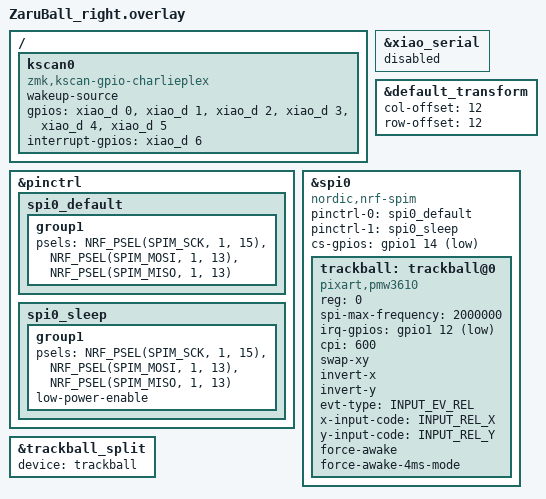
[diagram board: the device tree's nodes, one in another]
#include "ZaruBall.dtsi"
#include <input/processors.dtsi>
#include <dt-bindings/zmk/input_transform.h>

&xiao_serial { status = "disabled"; };

// matrix transformでのピン数オフセット
&default_transform { // Offset of 7 because the left side has 2 columns
    col-offset = <12>;
    row-offset = <12>;
};

/ {
    kscan0: kscan0 {
        compatible = "zmk,kscan-gpio-charlieplex";
        wakeup-source;
        gpios
            = <&xiao_d 0 GPIO_ACTIVE_HIGH>//M1
            , <&xiao_d 1 GPIO_ACTIVE_HIGH>//M2
            , <&xiao_d 2 GPIO_ACTIVE_HIGH>//M3
            , <&xiao_d 3 GPIO_ACTIVE_HIGH>//M4
            , <&xiao_d 4 GPIO_ACTIVE_HIGH>//M5
            , <&xiao_d 5 GPIO_ACTIVE_HIGH>//M6
            ;
        interrupt-gpios = <&xiao_d 6 (GPIO_ACTIVE_HIGH | GPIO_PULL_DOWN)>;//IGPIO
     };
};

&pinctrl {
    spi0_default: spi0_default {
        group1 {
            psels = <NRF_PSEL(SPIM_SCK, 1, 15)>,
                <NRF_PSEL(SPIM_MOSI, 1, 13)>,
                <NRF_PSEL(SPIM_MISO, 1, 13)>;
        };
    };

    spi0_sleep: spi0_sleep {
        group1 {
            psels = <NRF_PSEL(SPIM_SCK, 1, 15)>,
                <NRF_PSEL(SPIM_MOSI, 1, 13)>,
                <NRF_PSEL(SPIM_MISO, 1, 13)>;
            low-power-enable;
        };
    };
};

#include <zephyr/dt-bindings/input/input-event-codes.h>

&spi0 {
    status = "okay";
    compatible = "nordic,nrf-spim";
    pinctrl-0 = <&spi0_default>;
    pinctrl-1 = <&spi0_sleep>;
    pinctrl-names = "default", "sleep";
    cs-gpios = <&gpio1 14 GPIO_ACTIVE_LOW>;

    trackball: trackball@0 {
        status = "okay";
        compatible = "pixart,pmw3610";
        reg = <0>;
        spi-max-frequency = <2000000>;
        irq-gpios = <&gpio1 12 (GPIO_ACTIVE_LOW | GPIO_PULL_UP)>;
        cpi = <600>;
        swap-xy; /* optional */
        invert-x; /* optional */
        invert-y; /* optional */
        evt-type = <INPUT_EV_REL>;
        x-input-code = <INPUT_REL_X>;
        y-input-code = <INPUT_REL_Y>;

        force-awake;
        /* keep the sensor awake while ZMK activity state is ACTIVE,
           fallback to normal downshift mode after ZMK goes into IDLE / SLEEP mode.
           thus, the sensor would be a `wakeup-source` */

        force-awake-4ms-mode;
        /* while force-awake is acitvated, enable this mode to force sampling per 
           4ms, where the default sampling rate is 8ms. */
        /* NOTE: apply this mode if you need 250Hz with direct USB connection. */
    };
};

&trackball_split {
    status = "okay";
    device = <&trackball>;

    // Optional
    // input-processors = <&zip_xy_transform (INPUT_TRANSFORM_XY_SWAP | INPUT_TRANSFORM_X_INVERT | INPUT_TRANSFORM_Y_INVERT)>;
};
